# PMM__Power_Management_System_3 register map
Vendor: Texas Instruments
Peripheral module from a debugger description file (folder msp430).
Registers are 16-bit, read-write, reset 0x0 unless marked. A register's access mark holds for its fields unless they carry their own. Offsets are as the file gives them; lines under a group give offsets from that group; [hi:lo] are bit positions; {n}, {i} and the like mark numbered series; 'fields as' and 'values as' point back to an identical list; <NAME> marks a mode.

## PMM_Power_Management_System
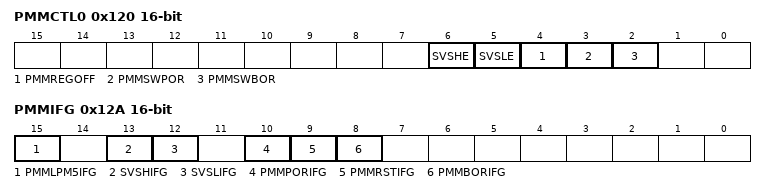
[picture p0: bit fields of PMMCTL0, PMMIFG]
0x120 PMMCTL0 — PMM Control 0
  [6] SVSHE — SVS high side enable
  [5] SVSLE — SVS low side enable
  [4] PMMREGOFF — PMM Turn Regulator off
  [3] PMMSWPOR — PMM Software POR
  [2] PMMSWBOR — PMM Software BOR
0x12A PMMIFG — PMM Interrupt Flag
  [15] PMMLPM5IFG — LPM5 indication Flag
  [13] SVSHIFG — SVS low side interrupt flag
  [12] SVSLIFG — SVS high side interrupt flag
  [10] PMMPORIFG — PMM Software POR interrupt flag
  [9] PMMRSTIFG — PMM RESET pin interrupt flag
  [8] PMMBORIFG — PMM Software BOR interrupt flag
0x130 PM5CTL0 — PMM Power Mode 5 Control Register 0
  [0] LOCKLPM5 — Lock I/O pin configuration upon entry/exit to/from LPM5
